# RA4M1 register map
Vendor: Renesas Electronics Corporation; Series: RA4; File version: 1.2
CPU: CM4 r0p1, little endian, MPU, FPU, VTOR, 4 interrupt priority bits
Registers are 8-bit, read-write, reset 0x0 unless marked. A register's access mark holds for its fields unless they carry their own. Offsets are from the block's base; [hi:lo] are bit positions; lines under a group give offsets from that group; {n}, {i} and the like mark numbered series; 'fields as' and 'values as' point back to an identical list; <NAME> marks a mode.

## ADC140 — 14bit A/D Converter
Base 0x4005C000
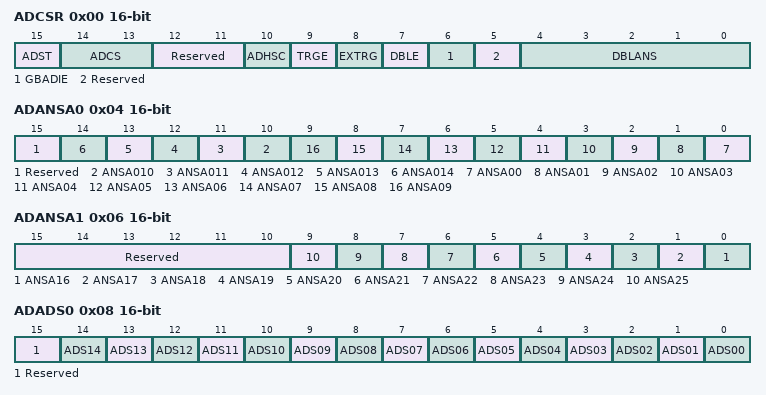
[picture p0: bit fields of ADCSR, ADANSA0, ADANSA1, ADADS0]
0x00 ADCSR 16-bit — A/D Control Register
  [15] ADST read-modifies — A/D Conversion Start
    0=Stops A/D conversion process; 1=Starts A/D conversion process
  [14:13] ADCS — Scan Mode Select
    0=Single scan mode; 1=Group scan mode; 2=Continuous scan mode; 3=Setting prohibited
  [12:11] Reserved — These bits are read as 00. The write value should be 00.
  [10] ADHSC — A/D Conversion Operation Mode Select
    0=High speed A/D conversion mode; 1=Low current A/D conversion mode
  [9] TRGE — Trigger Start Enable
    0=Disables A/D conversion to be started by the synchronous or asynchronous trigger; 1=Enables A/D conversion to be started by the synchronous or asynchronous trigger
  [8] EXTRG — Trigger Select
    0=A/D conversion is started by the synchronous trigger (ELC); 1=A/D conversion is started by the asynchronous trigger (ADTRG0#)
  [7] DBLE — Double Trigger Mode Select
    0=Double trigger mode non-selection; 1=Double trigger mode selection
  [6] GBADIE — Group B Scan End Interrupt Enable
    0=Disables S12GBADI0 interrupt generation upon group B scan completion; 1=Enables S12GBADI0 interrupt generation upon group B scan completion
  [5] Reserved — This bit is read as 0. The write value should be 0.
  [4:0] DBLANS — Double Trigger Channel Select These bits select one analog input channel for double triggered operation. The setting is only effective while double trigger mode is selected.
0x04 ADANSA0 16-bit — A/D Channel Select Register A0
  [15] Reserved — This bit is read as 0. The write value should be 0.
  [n] ANSA{n:03} (n=10..14) — AN{n:03} Select
    0=AN{n:03} is not subjected to conversion; 1=AN{n:03} is subjected to conversion
  [n] ANSA{n:02} (n=0..9) — AN{n:03} Select
    values as ANSA010
0x06 ADANSA1 16-bit — A/D Channel Select Register A1
  [15:10] Reserved — These bits are read as 000000. The write value should be 000000.
  [n-16] ANSA{n} (n=16..25) — AN{n:03} Select
    values as ADANSA0.ANSA010
0x08 ADADS0 16-bit — A/D-Converted Value Addition/Average Channel Select Register 0
  [15] Reserved — This bit is read as 0. The write value should be 0.
  [n] ADS{n:02} (n=0..14) — A/D-Converted Value Addition/Average Channel AN{n:03} Select
    0=AN{n:03} is not selected; 1=AN{n:03} is selected
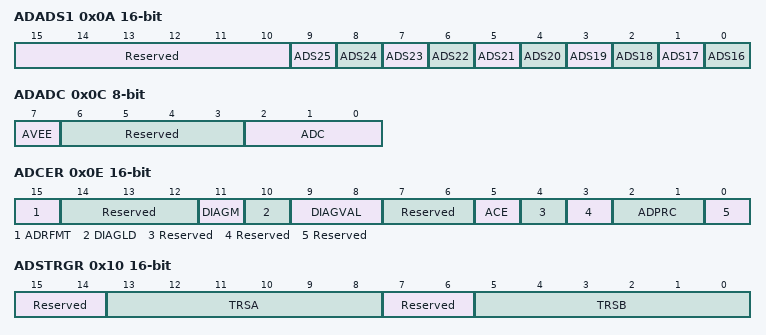
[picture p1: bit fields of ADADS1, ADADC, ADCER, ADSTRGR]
0x0A ADADS1 16-bit — A/D-Converted Value Addition/Average Channel Select Register 1
  [15:10] Reserved — These bits are read as 000000. The write value should be 000000.
  [n-16] ADS{n} (n=16..25) — A/D-Converted Value Addition/Average Channel AN{n:03} Select
    0=AN{n:03} is not selected; 1=AN{n:03} is selected
0x0C ADADC — A/D-Converted Value Addition/Average Count Select Register
  [7] AVEE — Average mode enable bit. Note: The AVEE bit converts twice, and only when converting it four times, is effective. Please do not set (ADADC.AVEE=1) to conversion (ADADC.ADC 2:0=010b) three times when you select the average mode.
    0=Disabled; 1=Enabled
  [6:3] Reserved — These bits are read as 0000. The write value should be 0000.
  [2:0] ADC — Addition frequency selection bit. NOTE: AVEE bit is valid at the only setting of ADC[2:0] bits = 001b or 011b. When average mode is selected by setting the ADADC.AVEE bit to 1, do not set the addition count to three times (ADADC.ADC[2:0] = 010b)
    0=1-time conversion (no addition; same as normal conversion); 1=2-time conversion (addition once); 2=3-time conversion (addition twice); 3=4-time conversion (addition three times); 5=16-time conversion (addition 15 times), can be set when selecting 12-bit accuracy; other=others (Setting prohibited)
0x0E ADCER 16-bit — A/D Control Extended Register
  [15] ADRFMT — A/D Data Register Format Select
    0=Flush-right is selected for the A/D data register format; 1=Flush-left is selected for the A/D data register format
  [14:12] Reserved — These bits are read as 000. The write value should be 000.
  [11] DIAGM — Self-Diagnosis Enable
    0=Disables self-diagnosis of A/D converter; 1=Enables self-diagnosis of A/D converter
  [10] DIAGLD — Self-Diagnosis Mode Select
    0=Rotation mode for self-diagnosis voltage; 1=Fixed mode for self-diagnosis voltage
  [9:8] DIAGVAL — Self-Diagnosis Conversion Voltage Select
    0=When the self-diagnosis fixation mode is selected, it set prohibits it; 1=The self-diagnosis by using the voltage of 0V; 2=The self-diagnosis by using the voltage of reference supply x 1/2; 3=The self-diagnosis by using the voltage of the reference supply
  [7:6] Reserved — These bits are read as 00. The write value should be 00.
  [5] ACE — A/D Data Register Automatic Clearing Enable
    0=Disables automatic clearing; 1=Enables automatic clearing
  [4] Reserved — This bit is read as 0. The write value should be 0.
  [3] Reserved — This bit is read as 0. The write value should be 0.
  [2:1] ADPRC — A/D Conversion Accuracy Specify
    0=A/D conversion is performed with 12-bit accuracy; 3=A/D conversion is performed with 14-bit accuracy; other=others (Setting prohibited)
  [0] Reserved — This bit is read as 0. The write value should be 0.
0x10 ADSTRGR 16-bit — A/D Conversion Start Trigger Select Register
  [15:14] Reserved — These bits are read as 00. The write value should be 00.
  [13:8] TRSA — A/D Conversion Start Trigger Select Select the A/D conversion start trigger in single scan mode and continuous mode. In group scan mode, the A/D conversion start trigger for group A is selected.
  [7:6] Reserved — These bits are read as 00. The write value should be 00.
  [5:0] TRSB — A/D Conversion Start Trigger Select for Group B Select the A/D conversion start trigger for group B in group scan mode.
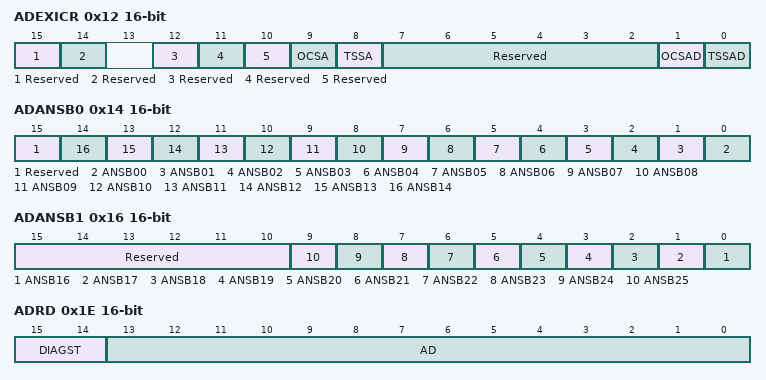
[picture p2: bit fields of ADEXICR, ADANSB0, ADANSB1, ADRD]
0x12 ADEXICR 16-bit — A/D Conversion Extended Input Control Register
  [15] Reserved — This bit is read as 0. The write value should be 0.
  [14] Reserved — This bit is read as 0. The write value should be 0.
  [12] Reserved — This bit is read as 0. The write value should be 0.
  [11] Reserved — This bit is read as 0. The write value should be 0.
  [10] Reserved — This bit is read as 0. The write value should be 0.
  [9] OCSA — Internal Reference Voltage A/D Conversion Select
    0=The internal reference voltage is not selected; 1=The internal reference voltage is selected for group A in single scan mode, continuous scan mode, or group scan mode
  [8] TSSA — Temperature Sensor Output A/D Conversion Select
    0=The temperature sensor output is not selected; 1=The temperature sensor output is selected
  [7:2] Reserved — These bits are read as 000000. The write value should be 000000.
  [1] OCSAD — Internal Reference Voltage A/D converted Value Addition/Average Mode Select
    0=Internal reference voltage A/D-converted value addition/average mode is not selected; 1=Internal reference voltage A/D-converted value addition/average mode is selected
  [0] TSSAD — Temperature Sensor Output A/D converted Value Addition/Average Mode Select
    0=Temperature sensor output A/D-converted value addition/average mode is not selected; 1=Temperature sensor output A/D-converted value addition/average mode is selected
0x14 ADANSB0 16-bit — A/D Channel Select Register B0
  [15] Reserved — This bit is read as 0. The write value should be 0.
  [n] ANSB{n:02} (n=0..14) — AN{n:03} Select
    values as ADANSA0.ANSA010
0x16 ADANSB1 16-bit — A/D Channel Select Register B1
  [15:10] Reserved — These bits are read as 000000. The write value should be 000000.
  [n-16] ANSB{n} (n=16..25) — AN{n:03} Select
    values as ADANSA0.ANSA010
0x18 ADDBLDR 16-bit ro — A/D Data Duplication Register
  [15:0] ADDBLDR — This is a 16-bit read-only register for storing the result of A/D conversion in response to the second trigger in double trigger mode.
0x1A ADTSDR 16-bit ro — A/D Temperature Sensor Data Register
  [15:0] ADTSDR — This is a 16-bit read-only register for storing the A/D conversion result of temperature sensor output.
0x1C ADOCDR 16-bit ro — A/D Internal Reference Voltage Data Register
  [15:0] ADOCDR — This is a 16-bit read-only register for storing the A/D result of internal reference voltage.
0x1E ADRD 16-bit ro — A/D Self-Diagnosis Data Register
  [15:14] DIAGST — Self-Diagnosis Status
    0=Self-diagnosis has never been executed since power-on; 1=Self-diagnosis using the voltage of 0 V has been executed; 2=Self-diagnosis using the voltage of reference power supply(VREFH) x 1/2 has been executed; 3=Self-diagnosis using the voltage of reference power supply(VREFH) has been executed
  [13:0] AD — A/D-converted value (right-justified) The format for data determine ADCER.ADRFMT and ADCER.ADPRC.
{0x20+2i} ADDR{i} (i=0..14) 16-bit ro — A/D Data Register {i}
  [15:0] ADDR — The ADDR register is a 16-bit read-only registers for storing the result of A/D conversion.
{0x20+2i} ADDR{i} (i=16..25) 16-bit ro — A/D Data Register {i}
  fields as ADDR0
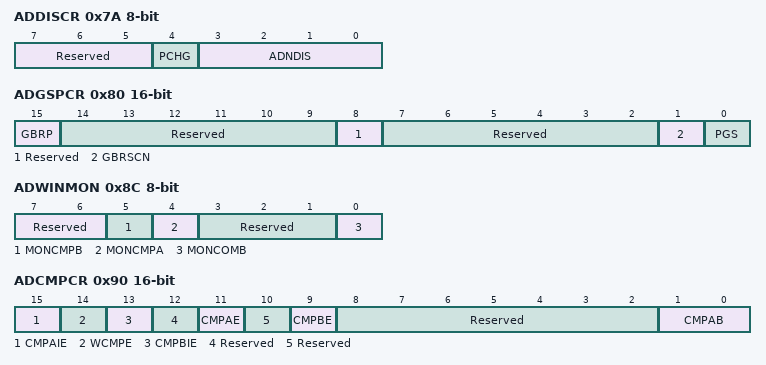
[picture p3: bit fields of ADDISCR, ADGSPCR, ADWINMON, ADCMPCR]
0x7A ADDISCR — A/D Disconnection Detection Control Register
  [7:5] Reserved — These bits are read as 000. The write value should be 000.
  [4] PCHG — Selection of Precharge or Discharge
    0=Discharge; 1=Precharge
  [3:0] ADNDIS — The charging time
    0=Disconnection detection is disabled; 1=Setting prohibited; other=others (( 1 / ADCLK ) x ADNDIS)
0x80 ADGSPCR 16-bit — A/D Group Scan Priority Control Register
  [15] GBRP — Group B Single Scan Continuous Start (Enabled only when PGS = 1. Reserved when PGS = 0.) Note: When the GBRP bit has been set to 1, single scan is performed continuously for group B regardless of the setting of the GBRSCN bit.
    0=Single scan for group B is not continuously activated; 1=Single scan for group B is continuously activated
  [14:9] Reserved — These bits are read as 000000. The write value should be 000000.
  [8] Reserved — This bit is read as 0. The write value should be 0.
  [7:2] Reserved — These bits are read as 000000. The write value should be 000000.
  [1] GBRSCN — Group B Restart Setting (Enabled only when PGS = 1. Reserved when PGS = 0.)
    0=Scanning for group B is not restarted after having been discontinued due to group A priority control; 1=Scanning for group B is restarted after having been discontinued due to group A priority control
  [0] PGS — Group A priority control setting bit. Note: When the PGS bit is to be set to 1, the ADCSR.ADCS[1:0] bits must be set to 01b (group scan mode). If the bits are set to any other values, proper operation is not guaranteed.
    0=Operation is without group A priority control; 1=Operation is with group A priority control
0x84 ADDBLDRA 16-bit ro — A/D Data Duplexing Register A
  [15:0] ADDBLDRA — This register is a 16-bit read-only registers for storing the result of A/D conversion in response to the respective triggers during extended operation in double trigger mode.
0x86 ADDBLDRB 16-bit ro — A/D Data Duplexing Register B
  [15:0] ADDBLDRB — This register is a 16-bit read-only registers for storing the result of A/D conversion in response to the respective triggers during extended operation in double trigger mode.
0x8A ADHVREFCNT — A/D High-Potential/Low-Potential Reference Voltage Control Register
  [7] ADSLP — Sleep
    0=Normal operation; 1=Standby state
  [6:5] Reserved — These bits are read as 00. The write value should be 00.
  [4:2] LVSEL — Low-Potential Reference Voltage Select
    0=AVSS0 is selected as the low-potential reference voltage; 1=VREFL0 is selected as the low-potential reference voltage
  [3:2] Reserved — These bits are read as 00. The write value should be 00.
  [1:0] HVSEL — High-Potential Reference Voltage Select
    0=AVCC0 is selected as the high-potential reference voltage; 1=VREFH0 is selected as the high-potential reference voltage; 2=Internal reference voltage is selected as the high-potential reference voltage; 3=Internal node discharge. No reference voltage pin is selected.
0x8C ADWINMON ro — A/D Compare Function Window A/B Status Monitor Register
  [7:6] Reserved — These bits are read as 00.
  [5] MONCMPB — Comparison Result Monitor B
    0=Window B comparison conditions are not met; 1=Window B comparison conditions are met
  [4] MONCMPA — Comparison Result Monitor A
    0=Window A comparison conditions are not met; 1=Window A comparison conditions are met
  [3:1] Reserved — These bits are read as 000.
  [0] MONCOMB — Combination result monitor This bit indicates the combination result. This bit is valid when both window A operation and window B operation are enabled.
    0=Window A / window B composite conditions are not met; 1=Window A / window B composite conditions are met
0x90 ADCMPCR 16-bit — A/D Compare Function Control Register
  [15] CMPAIE — Compare A Interrupt Enable
    0=ADC140_CMPAI interrupt is disabled when comparison conditions (window A) are met; 1=ADC140_CMPAI interrupt is enabled when comparison conditions (window A) are met
  [14] WCMPE — Window Function Setting
    0=Window function is disabled. Window A and window B operate as a comparator to comparator the single value on the lower side with the A/D conversion result.; 1=Window function is enabled. Window A and window B operate as a comparator to comparator the two values on the upper and lower sides with the A/D conversion result.
  [13] CMPBIE — Compare B Interrupt Enable
    0=ADC140_CMPAI interrupt is disabled when comparison conditions (window B) are met; 1=ADC140_CMPAI interrupt is enabled when comparison conditions (window B) are met
  [12] Reserved — This bit is read as 0. The write value should be 0.
  [11] CMPAE — Compare Window A Operation Enable
    0=Compare window A operation is disabled. ADC140_WCMPM and ADC140_WCMPUM outputs are disabled.; 1=Compare window A operation is enabled
  [10] Reserved — This bit is read as 0. The write value should be 0.
  [9] CMPBE — Compare Window B Operation Enable
    0=Compare window B operation is disabled. ADC140_WCMPM and ADC140_WCMPUM outputs are disabled.; 1=Compare window B operation is enabled
  [8:2] Reserved — These bits are read as 0000000. The write value should be 0000000.
  [1:0] CMPAB — Window A/B Composite Conditions Setting NOTE: These bits are valid when both window A and window B are enabled (CMPAE = 1 and CMPBE = 1).
    0=ADC140_WCMPM is output when window A comparison conditions are met OR window B comparison conditions are met. ADC140_WCMPUM is output in other cases.; 1=S14ADWMELC0 is output when window A comparison conditions are met EXOR window B comparison conditions are met. ADC140_WCMPUM is output in other cases.; 2=ADC140_WCMPM is output when window A comparison conditions are met and window B comparison conditions are met. ADC140_WCMPUM is output in other cases.; 3=Setting prohibited
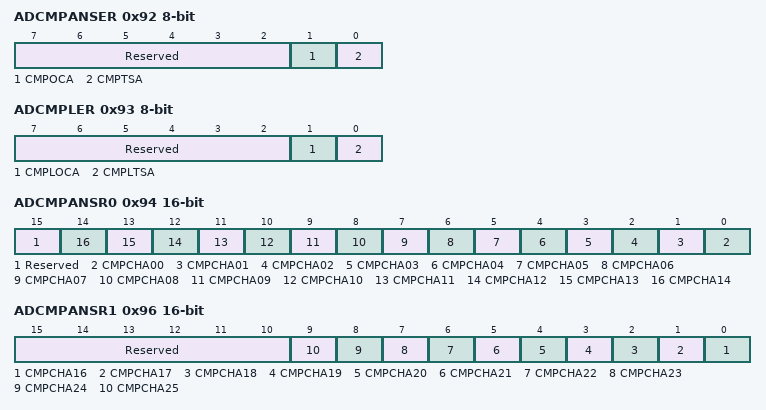
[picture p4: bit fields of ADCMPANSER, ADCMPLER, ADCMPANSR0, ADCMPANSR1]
0x92 ADCMPANSER — A/D Compare Function Window A Extended Input Select Register
  [7:2] Reserved — These bits are read as 000000. The write value should be 000000.
  [1] CMPOCA — Internal reference voltage Compare selection bit.
    0=Excludes the internal reference voltage from the compare window A target range; 1=Includes the internal reference voltage in the compare window A target range
  [0] CMPTSA — Temperature sensor output Compare selection bit.
    0=Excludes the temperature sensor output from the compare window A target range; 1=Includes the temperature sensor output in the compare window A target range
0x93 ADCMPLER — A/D Compare Function Window A Extended Input Comparison Condition Setting Register
  [7:2] Reserved — These bits are read as 000000. The write value should be 000000.
  [1] CMPLOCA — Compare Window A Internal Reference Voltage Comparison Condition Select
    0=ADCMPDR0 value > A/D converted value(ADCMPCR.WCMPE=0) / A/D converted value < ADCMPDR0 value or A/D converted value > ADCMPDR1 value (ADCMPCR.WCMPE=1); 1=ADCMPDR0 value < A/D converted value(ADCMPCR.WCMPE=0) / ADCMPDR0 value < A/D converted value < ADCMPDR1 value(ADCMPCR.WCMPE=1)
  [0] CMPLTSA — Compare Window A Temperature Sensor Output Comparison Condition Select
    0=ADCMPDR0 register value > A/D-converted value(ADCMPCR.WCMPE=0) / AD-converted value < ADCMPDR0 register value or A/D-converted value > ADCMPDR1 register value(ADCMPCR.WCMPE=1); 1=ADCMPDR0 register value < A/D-converted value(ADCMPCR.WCMPE=0) / ADCMPDR0 register value < A/D-converted value < ADCMPDR1 register value(ADCMPCR.WCMPE=1)
0x94 ADCMPANSR0 16-bit — A/D Compare Function Window A Channel Select Register 0
  [15] Reserved — This bit is read as 0. The write value should be 0.
  [n] CMPCHA{n:02} (n=0..14) — AN{n:03} Select
    0=Excludes AN{n:03} from the compare window A target range; 1=Includes AN{n:03} from the compare window A target range
0x96 ADCMPANSR1 16-bit — A/D Compare Function Window A Channel Select Register 1
  [15:10] Reserved — These bits are read as 000000. The write value should be 000000.
  [n-16] CMPCHA{n} (n=16..25) — AN{n:03} Select
    values as ADCMPANSR0.CMPCHA00
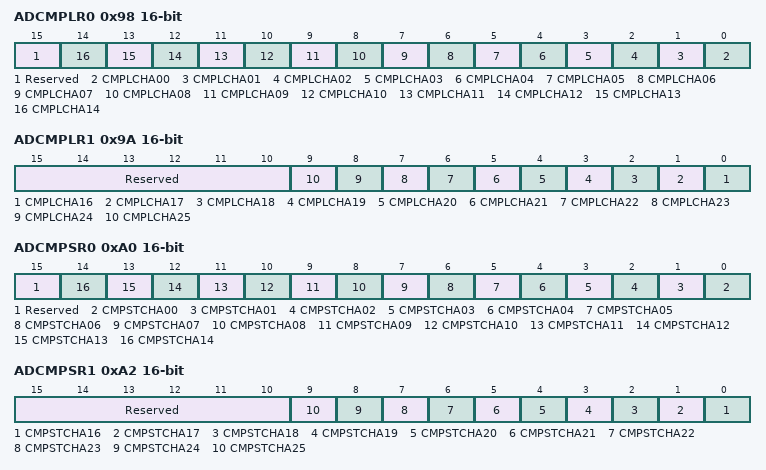
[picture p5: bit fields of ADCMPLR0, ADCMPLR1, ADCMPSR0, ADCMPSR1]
0x98 ADCMPLR0 16-bit — A/D Compare Function Window A Comparison Condition Setting Register 0
  [15] Reserved — This bit is read as 0. The write value should be 0.
  [n] CMPLCHA{n:02} (n=0..14) — Comparison condition of AN{n:03}
    0=ADCMPDR0 value > A/D converted value (ADCMPCR.WCMPE=0) / A/D converted value < ADCMPDR0 value or, ADCMPDR1 value < A/D converted value (ADCMPCR.WCMPE=1); 1=ADCMPDR0 value < A/D converted value (ADCMPCR.WCMPE=0) / A/DCMPDR0 value < A/D converted value < ADCMPDR1 value (ADCMPCR.WCMPE=1)
0x9A ADCMPLR1 16-bit — A/D Compare Function Window A Comparison Condition Setting Register 1
  [15:10] Reserved — These bits are read as 000000. The write value should be 000000.
  [n-16] CMPLCHA{n} (n=16..25) — Comparison condition of AN{n:03}
    values as ADCMPLR0.CMPLCHA00
0x9C ADCMPDR0 16-bit — A/D Compare Function Window A Lower-Side Level Setting Register
  [15:0] ADCMPDR0 — The ADCMPDR0 register sets the reference data when the compare window A function is used. ADCMPDR0 sets the lower-side level of window A.
0x9E ADCMPDR1 16-bit — A/D Compare Function Window A Upper-Side Level Setting Register
  [15:0] ADCMPDR1 — The ADCMPDR1 register sets the reference data when the compare window A function is used. ADCMPDR1 sets the upper-side level of window A..
0xA0 ADCMPSR0 16-bit — A/D Compare Function Window A Channel Status Register 0
  [15] Reserved — This bit is read as 0. The write value should be 0.
  [n] CMPSTCHA{n:02} write-0-clears read-modifies (n=0..14) — Compare window A flag of AN{n:03}
    0=Comparison conditions are not met; 1=Comparison conditions are met
0xA2 ADCMPSR1 16-bit — A/D Compare Function Window A Channel Status Register 1
  [15:10] Reserved — These bits are read as 000000. The write value should be 000000.
  [n-16] CMPSTCHA{n} write-0-clears read-modifies (n=16..25) — Compare window A flag of AN{n:03}
    values as ADCMPSR0.CMPSTCHA00
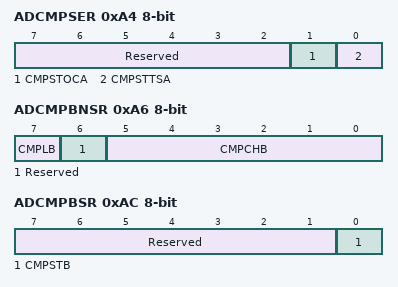
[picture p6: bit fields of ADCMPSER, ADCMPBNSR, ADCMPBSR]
0xA4 ADCMPSER — A/D Compare Function Window A Extended Input Channel Status Register
  [7:2] Reserved — These bits are read as 000000. The write value should be 000000.
  [1] CMPSTOCA write-0-clears read-modifies — Compare Window A Internal Reference Voltage Compare Flag When window A operation is enabled (ADCMPCR.CMPAE = 1b), this bit indicates the temperature sensor output comparison result. When window A operation is disabled (ADCMPCR.CMPAE = 0b), comparison conditions for CMPSTTSA are not met any time.
    values as ADCMPSR0.CMPSTCHA00
  [0] CMPSTTSA write-0-clears read-modifies — Compare Window A Temperature Sensor Output Compare Flag When window A operation is enabled (ADCMPCR.CMPAE = 1b), this bit indicates the temperature sensor output comparison result. When window A operation is disabled (ADCMPCR.CMPAE = 0b), comparison conditions for CMPSTTSA are not met any time.
    values as ADCMPSR0.CMPSTCHA00
0xA6 ADCMPBNSR — A/D Compare Function Window B Channel Selection Register
  [7] CMPLB — Compare window B Compare condition setting bit.
    0=CMPLLB value > A/D converted value (ADCMPCR.WCMPE=0) / A/D converted value < CMPLLB value or CMPULB value < A/D converted value (ADCMPCR.WCMPE=1); 1=CMPLLB value < A/D converted value(ADCMPCR.WCMPE=0) / CMPLLB value < A/D converted value < CMPULB value (ADCMPCR.WCMPE=1)
  [6] Reserved — This bit is read as 0. The write value should be 0.
  [5:0] CMPCHB — Compare window B channel selection bit. The channel that compares it on the condition of compare window B is selected.
    {v}=AN{v:03} (v=0..27); 32=Temperature sensor; 33=Internal reference voltage; 63=No channel is selected; other=others (Setting prohibited)
0xA8 ADWINLLB 16-bit — A/D Compare Function Window B Lower-Side Level Setting Register
  [15:0] ADWINLLB — This register is used to compare A window function is used to set the lower level of the window B.
0xAA ADWINULB 16-bit — A/D Compare Function Window B Upper-Side Level Setting Register
  [15:0] ADWINULB — This register is used to compare A window function is used to set the higher level of the window B.
0xAC ADCMPBSR — A/D Compare Function Window B Status Register
  [7:1] Reserved — These bits are read as 0000000. The write value should be 0000000.
  [0] CMPSTB write-0-clears read-modifies — Compare window B flag. It is a status flag that shows the comparative result of CH (AN000-AN027, temperature sensor, and internal reference voltage) made the object of window B relation condition.
    values as ADCMPSR0.CMPSTCHA00
0xDD ADSSTRL reset 0xD — A/D Sampling State Register L
  [7:0] SST range 0x05..0xFF — Sampling Time Setting (AN016-AN027)
0xDE ADSSTRT reset 0xD — A/D Sampling State Register T
  [7:0] SST range 0x05..0xFF — Sampling Time Setting (temperature sensor output)
0xDF ADSSTRO reset 0xD — A/D Sampling State Register O
  [7:0] SST range 0x05..0xFF — Sampling Time Setting (Internal reference voltage)
{0xE0+i} ADSSTR{i} (i=0..14) reset 0xD — A/D Sampling State Register {i}
  [7:0] SST range 0x05..0xFF — Sampling time setting
